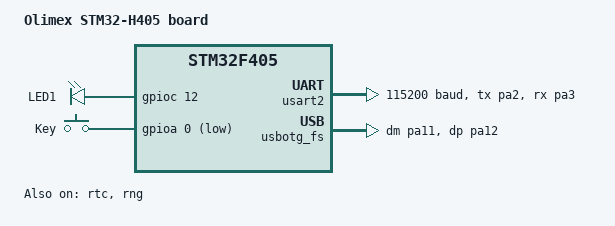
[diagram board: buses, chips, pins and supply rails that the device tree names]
/*
 * Copyright (c) 2020, Antony Pavlov <antonynpavlov@gmail.com>
 *
 * SPDX-License-Identifier: Apache-2.0
 */

/dts-v1/;
#include <st/f4/stm32f405Xg.dtsi>
#include <st/f4/stm32f405rgtx-pinctrl.dtsi>

/ {
	model = "Olimex STM32-H405 board";
	compatible = "olimex,stm32-h405", "st,stm32f405";

	chosen {
		zephyr,console = &usart2;
		zephyr,shell-uart = &usart2;
		zephyr,sram = &sram0;
		zephyr,flash = &flash0;
		zephyr,ccm = &ccm0;
	};

	leds {
		compatible = "gpio-leds";
		green_led_1: led_1 {
			gpios = <&gpioc 12 GPIO_ACTIVE_HIGH>;
			label = "LED1";
		};
	};

	gpio_keys {
		compatible = "gpio-keys";
		user_button: button {
			label = "Key";
			gpios = <&gpioa 0 GPIO_ACTIVE_LOW>;
		};
	};

	aliases {
		led0 = &green_led_1;
		sw0 = &user_button;
	};
};

&usart2 {
	pinctrl-0 = <&usart2_tx_pa2 &usart2_rx_pa3>;
	current-speed = <115200>;
	status = "okay";
};

&rtc {
	status = "okay";
};

&rng {
	status = "okay";
};

usb_otg: &usbotg_fs {
	pinctrl-0 = <&usb_otg_fs_dm_pa11 &usb_otg_fs_dp_pa12>;
	status = "okay";
	label = "CDC_ACM_0";
};
